# fcr_es17 register map
Registers are read-write, no defined reset value unless marked. A register's access mark holds for its fields unless they carry their own. Offsets are from the block's base; lines under a group give offsets from that group; [hi:lo] are bit positions; {n}, {i} and the like mark numbered series; 'fields as' and 'values as' point back to an identical list; <NAME> marks a mode.

## Memory map
0x40000800 FCR size 0x400 — Function Control Register.

## FCR — Function Control Register.
Base 0x40000800
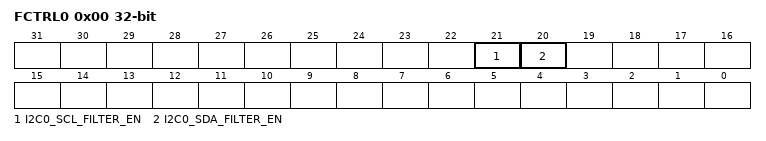
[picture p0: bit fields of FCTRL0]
0x00 FCTRL0 — Register 0.
  [21] I2C0_SCL_FILTER_EN — I2C0 SCL Glitch Filter Enable.
    0=dis (Filter disabled.); 1=en (Filter enabled.)
  [20] I2C0_SDA_FILTER_EN — I2C0 SDA Glitch Filter Enable.
    0=dis (Filter disabled.); 1=en (Filter enabled.)
